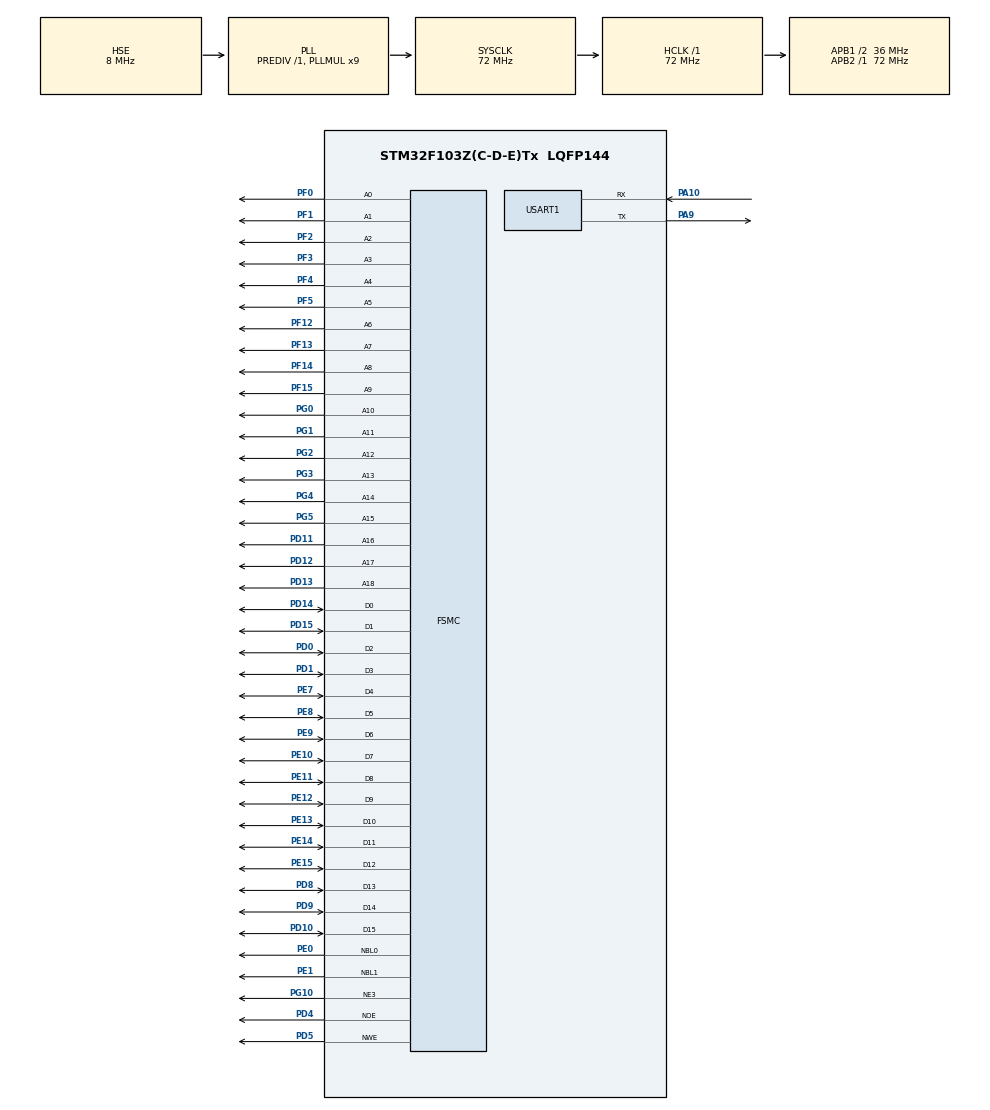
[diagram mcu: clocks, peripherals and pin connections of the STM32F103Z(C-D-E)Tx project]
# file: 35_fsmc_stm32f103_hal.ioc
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FSMC.DataSetupTime3=4
FSMC.WriteOperation3=FSMC_WRITE_OPERATION_ENABLE
Mcu.Family=STM32F1
Mcu.Name=STM32F103Z(C-D-E)Tx
Mcu.Package=LQFP144
NVIC.PriorityGroup=NVIC_PRIORITYGROUP_4
OSC_IN.Mode=HSE-External-Oscillator
OSC_IN.Signal=RCC_OSC_IN
OSC_OUT.Mode=HSE-External-Oscillator
OSC_OUT.Signal=RCC_OSC_OUT
PA10.Mode=Asynchronous
PA10.Signal=USART1_RX
PA13.Mode=Serial_Wire
PA13.Signal=SYS_JTMS-SWDIO
PA14.Mode=Serial_Wire
PA14.Signal=SYS_JTCK-SWCLK
PA9.Mode=Asynchronous
PA9.Signal=USART1_TX
PD0.Signal=FSMC_D2_DA2
PD1.Signal=FSMC_D3_DA3
PD10.Signal=FSMC_D15_DA15
PD11.Signal=FSMC_A16_CLE
PD12.Signal=FSMC_A17_ALE
PD13.Signal=FSMC_A18
PD14.Signal=FSMC_D0_DA0
PD15.Signal=FSMC_D1_DA1
PD4.Signal=FSMC_NOE
PD5.Signal=FSMC_NWE
PD8.Signal=FSMC_D13_DA13
PD9.Signal=FSMC_D14_DA14
PE0.Signal=FSMC_NBL0
PE1.Signal=FSMC_NBL1
PE10.Signal=FSMC_D7_DA7
PE11.Signal=FSMC_D8_DA8
PE12.Signal=FSMC_D9_DA9
PE13.Signal=FSMC_D10_DA10
PE14.Signal=FSMC_D11_DA11
PE15.Signal=FSMC_D12_DA12
PE7.Signal=FSMC_D4_DA4
PE8.Signal=FSMC_D5_DA5
PE9.Signal=FSMC_D6_DA6
PF0.Signal=FSMC_A0
PF1.Signal=FSMC_A1
PF12.Signal=FSMC_A6
PF13.Signal=FSMC_A7
PF14.Signal=FSMC_A8
PF15.Signal=FSMC_A9
PF2.Signal=FSMC_A2
PF3.Signal=FSMC_A3
PF4.Signal=FSMC_A4
PF5.Signal=FSMC_A5
PG0.Signal=FSMC_A10
PG1.Signal=FSMC_A11
PG10.Mode=NorPsramChipSelect3_3
PG10.Signal=FSMC_NE3
PG2.Signal=FSMC_A12
PG3.Signal=FSMC_A13
PG4.Signal=FSMC_A14
PG5.Signal=FSMC_A15
ProjectManager.HeapSize=0x200
ProjectManager.StackSize=0x400
ProjectManager.TargetToolchain=MDK-ARM V5.32
RCC.AHBFreq_Value=72000000
RCC.APB1CLKDivider=RCC_HCLK_DIV2
RCC.APB1Freq_Value=36000000
RCC.APB1TimFreq_Value=72000000
RCC.APB2Freq_Value=72000000
RCC.APB2TimFreq_Value=72000000
RCC.HCLKFreq_Value=72000000
RCC.PLLMUL=RCC_PLL_MUL9
RCC.PLLSourceVirtual=RCC_PLLSOURCE_HSE
RCC.SYSCLKFreq_VALUE=72000000
RCC.SYSCLKSource=RCC_SYSCLKSOURCE_PLLCLK
RCC.USBFreq_Value=72000000
SH.FSMC_A0.0=FSMC_A0,19b-a3
SH.FSMC_A1.0=FSMC_A1,19b-a3
SH.FSMC_A10.0=FSMC_A10,19b-a3
SH.FSMC_A11.0=FSMC_A11,19b-a3
SH.FSMC_A12.0=FSMC_A12,19b-a3
SH.FSMC_A13.0=FSMC_A13,19b-a3
SH.FSMC_A14.0=FSMC_A14,19b-a3
SH.FSMC_A15.0=FSMC_A15,19b-a3
SH.FSMC_A16_CLE.0=FSMC_A16,19b-a3
SH.FSMC_A17_ALE.0=FSMC_A17,19b-a3
SH.FSMC_A18.0=FSMC_A18,19b-a3
SH.FSMC_A2.0=FSMC_A2,19b-a3
SH.FSMC_A3.0=FSMC_A3,19b-a3
SH.FSMC_A4.0=FSMC_A4,19b-a3
SH.FSMC_A5.0=FSMC_A5,19b-a3
SH.FSMC_A6.0=FSMC_A6,19b-a3
SH.FSMC_A7.0=FSMC_A7,19b-a3
SH.FSMC_A8.0=FSMC_A8,19b-a3
SH.FSMC_A9.0=FSMC_A9,19b-a3
SH.FSMC_D0_DA0.0=FSMC_D0,16b-d3
SH.FSMC_D10_DA10.0=FSMC_D10,16b-d3
SH.FSMC_D11_DA11.0=FSMC_D11,16b-d3
SH.FSMC_D12_DA12.0=FSMC_D12,16b-d3
SH.FSMC_D13_DA13.0=FSMC_D13,16b-d3
SH.FSMC_D14_DA14.0=FSMC_D14,16b-d3
SH.FSMC_D15_DA15.0=FSMC_D15,16b-d3
SH.FSMC_D1_DA1.0=FSMC_D1,16b-d3
SH.FSMC_D2_DA2.0=FSMC_D2,16b-d3
SH.FSMC_D3_DA3.0=FSMC_D3,16b-d3
SH.FSMC_D4_DA4.0=FSMC_D4,16b-d3
SH.FSMC_D5_DA5.0=FSMC_D5,16b-d3
SH.FSMC_D6_DA6.0=FSMC_D6,16b-d3
SH.FSMC_D7_DA7.0=FSMC_D7,16b-d3
SH.FSMC_D8_DA8.0=FSMC_D8,16b-d3
SH.FSMC_D9_DA9.0=FSMC_D9,16b-d3
SH.FSMC_NBL0.0=FSMC_NBL0,2ByteEnable3
SH.FSMC_NBL1.0=FSMC_NBL1,2ByteEnable3
SH.FSMC_NOE.0=FSMC_NOE,Sram3
SH.FSMC_NWE.0=FSMC_NWE,Sram3
USART1.VirtualMode=VM_ASYNC
board=custom

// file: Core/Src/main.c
/* USER CODE BEGIN Header */
/**
  ******************************************************************************
  * @file           : main.c
  * @brief          : Main program body
  ******************************************************************************
  * @attention
  *
  * Copyright (c) 2025 STMicroelectronics.
  * All rights reserved.
  *
  * This software is licensed under terms that can be found in the LICENSE file
  * in the root directory of this software component.
  * If no LICENSE file comes with this software, it is provided AS-IS.
  *
  ******************************************************************************
  */
/* USER CODE END Header */
#include "main.h"
#include "usart.h"
#include "gpio.h"
#include "fsmc.h"

void SystemClock_Config(void);

int main(void)
{

  /* MCU Configuration--------------------------------------------------------*/

  /* Reset of all peripherals, Initializes the Flash interface and the Systick. */
  HAL_Init();

  /* Configure the system clock */
  SystemClock_Config();

  /* Initialize all configured peripherals */
  MX_GPIO_Init();
  MX_FSMC_Init();
  MX_USART1_UART_Init();
  /* USER CODE BEGIN 2 */
  uint16_t *p = (uint16_t *)0x68000000;
	*p = 44444;
	uint8_t *f = (uint8_t *)0x68000002;
	*f = 33;
  /* USER CODE END 2 */

  /* Infinite loop */
  /* USER CODE BEGIN WHILE */
  while (1)
  {
    printf("p = %d, @p = %p\r\n", *p, p);
		printf("f = %d, @p = %p\r\n", *f, f);
    HAL_Delay(1000);
    /* USER CODE END WHILE */

  }
}

void SystemClock_Config(void)
{
  RCC_OscInitTypeDef RCC_OscInitStruct = {0};
  RCC_ClkInitTypeDef RCC_ClkInitStruct = {0};

  /** Initializes the RCC Oscillators according to the specified parameters
  * in the RCC_OscInitTypeDef structure.
  */
  RCC_OscInitStruct.OscillatorType = RCC_OSCILLATORTYPE_HSE;
  RCC_OscInitStruct.HSEState = RCC_HSE_ON;
  RCC_OscInitStruct.HSEPredivValue = RCC_HSE_PREDIV_DIV1;
  RCC_OscInitStruct.HSIState = RCC_HSI_ON;
  RCC_OscInitStruct.PLL.PLLState = RCC_PLL_ON;
  RCC_OscInitStruct.PLL.PLLSource = RCC_PLLSOURCE_HSE;
  RCC_OscInitStruct.PLL.PLLMUL = RCC_PLL_MUL9;
  if (HAL_RCC_OscConfig(&RCC_OscInitStruct) != HAL_OK)
  {
    Error_Handler();
  }

  /** Initializes the CPU, AHB and APB buses clocks
  */
  RCC_ClkInitStruct.ClockType = RCC_CLOCKTYPE_HCLK|RCC_CLOCKTYPE_SYSCLK
                              |RCC_CLOCKTYPE_PCLK1|RCC_CLOCKTYPE_PCLK2;
  RCC_ClkInitStruct.SYSCLKSource = RCC_SYSCLKSOURCE_PLLCLK;
  RCC_ClkInitStruct.AHBCLKDivider = RCC_SYSCLK_DIV1;
  RCC_ClkInitStruct.APB1CLKDivider = RCC_HCLK_DIV2;
  RCC_ClkInitStruct.APB2CLKDivider = RCC_HCLK_DIV1;

  if (HAL_RCC_ClockConfig(&RCC_ClkInitStruct, FLASH_LATENCY_2) != HAL_OK)
  {
    Error_Handler();
  }
}

void Error_Handler(void)
{
  __disable_irq();
  while (1)
  {
  }
}
